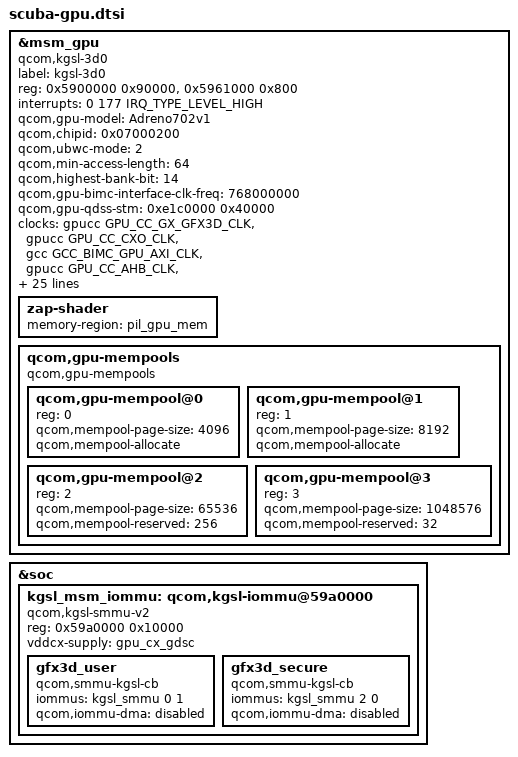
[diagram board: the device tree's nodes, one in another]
#define MHZ_TO_KBPS(mhz, w) ((mhz * 1000000 * w) / (1024))

&msm_gpu {
	label = "kgsl-3d0";
	compatible = "qcom,kgsl-3d0", "qcom,kgsl-3d";
	status = "ok";

	reg = <0x5900000 0x90000>,
		<0x5961000 0x800>;
	reg-names = "kgsl_3d0_reg_memory", "cx_dbgc";

	interrupts = <0 177 IRQ_TYPE_LEVEL_HIGH>;
	interrupt-names = "kgsl_3d0_irq";

	qcom,gpu-model = "Adreno702v1";
	qcom,chipid = <0x07000200>;

	qcom,ubwc-mode = <2>;
	qcom,min-access-length = <64>;
	qcom,highest-bank-bit = <14>;
	qcom,gpu-bimc-interface-clk-freq = <768000000>;

	/* base addr, size */
	qcom,gpu-qdss-stm = <0xe1c0000 0x40000>;
	#cooling-cells = <2>;

	clocks = <&gpucc GPU_CC_GX_GFX3D_CLK>,
		<&gpucc GPU_CC_CXO_CLK>,
		<&gcc GCC_BIMC_GPU_AXI_CLK>,
		<&gpucc GPU_CC_AHB_CLK>,
		<&gcc GCC_GPU_MEMNOC_GFX_CLK>,
		<&gpucc GPU_CC_CX_GMU_CLK>,
		<&gpucc GPU_CC_HLOS1_VOTE_GPU_SMMU_CLK>,
		<&rpmcc RPM_SMD_BIMC_GPU_CLK>,
		<&gpucc GPU_CC_AHB_CLK>,
		<&gcc GCC_GPU_MEMNOC_GFX_CLK>,
		<&gpucc GPU_CC_HLOS1_VOTE_GPU_SMMU_CLK>,
		<&gcc GCC_GPU_SNOC_DVM_GFX_CLK>;

	clock-names = "core_clk",
		"rbbmtimer_clk",
		"mem_clk",
		"iface_clk",
		"mem_iface_clk",
		"gmu_clk",
		"smmu_vote",
		"bimc_gpu_clk",
		"gpu_cc_ahb",
		"gcc_gpu_memnoc_gfx",
		"gpu_cc_hlos1_vote_gpu_smmu",
		"gcc_gpu_snoc_dvm_gfx";

	interconnects = <&bimc MASTER_GRAPHICS_3D &bimc SLAVE_EBI_CH0>;
	interconnect-names = "gpu_icc_path";

	qcom,bus-table-ddr =
		<MHZ_TO_KBPS(0, 8)>,    /* index=0  */
		<MHZ_TO_KBPS(100, 8)>,  /* index=1  */
		<MHZ_TO_KBPS(200, 8)>,  /* index=2  */
		<MHZ_TO_KBPS(300, 8)>,  /* index=3  */
		<MHZ_TO_KBPS(451, 8)>,  /* index=4  */
		<MHZ_TO_KBPS(547, 8)>,  /* index=5  */
		<MHZ_TO_KBPS(681, 8)>,  /* index=6  */
		<MHZ_TO_KBPS(768, 8)>,  /* index=7  */
		<MHZ_TO_KBPS(1017, 8)>, /* index=8  */
		<MHZ_TO_KBPS(1353, 8)>, /* index=9  */
		<MHZ_TO_KBPS(1555, 8)>, /* index=10 */
		<MHZ_TO_KBPS(1804, 8)>; /* index=11 */

	/* GDSC regulator names */
	regulator-names = "vddcx", "vdd";
	/* GDSC oxili regulators */
	vddcx-supply = <&gpu_cx_gdsc>;
	vdd-supply = <&gpu_gx_gdsc>;

	/* Enable context aware freq. scaling */
	qcom,enable-ca-jump;
	/* Context aware jump busy penalty in us */
	qcom,ca-busy-penalty = <12000>;
	/* Context aware jump target power level */
	qcom,ca-target-pwrlevel = <5>;

	nvmem-cells = <&gpu_speed_bin>;
	nvmem-cell-names = "speed_bin";

	/* ZAP Shader memory */
	zap-shader {
		memory-region = <&pil_gpu_mem>;
	};

	/* GPU Mempools */
	qcom,gpu-mempools {
		#address-cells = <1>;
		#size-cells = <0>;
		compatible = "qcom,gpu-mempools";

		/* 4K Page Pool configuration */
		qcom,gpu-mempool@0 {
			reg = <0>;
			qcom,mempool-page-size = <4096>;
			qcom,mempool-allocate;
		};
		/* 8K Page Pool configuration */
		qcom,gpu-mempool@1 {
			reg = <1>;
			qcom,mempool-page-size = <8192>;
			qcom,mempool-allocate;
		};
		/* 64K Page Pool configuration */
		qcom,gpu-mempool@2 {
			reg = <2>;
			qcom,mempool-page-size = <65536>;
			qcom,mempool-reserved = <256>;
		};
		/* 1M Page Pool configuration */
		qcom,gpu-mempool@3 {
			reg = <3>;
			qcom,mempool-page-size = <1048576>;
			qcom,mempool-reserved = <32>;
		};
	};
};

&soc {
	kgsl_msm_iommu: qcom,kgsl-iommu@59a0000 {
		compatible = "qcom,kgsl-smmu-v2";
		reg = <0x59a0000 0x10000>;

		vddcx-supply = <&gpu_cx_gdsc>;

		gfx3d_user: gfx3d_user {
			compatible = "qcom,smmu-kgsl-cb";
			iommus = <&kgsl_smmu 0 1>;
			qcom,iommu-dma = "disabled";
		};

		gfx3d_secure: gfx3d_secure {
			compatible = "qcom,smmu-kgsl-cb";
			iommus = <&kgsl_smmu 2 0>;
			qcom,iommu-dma = "disabled";
		};
	};
};
